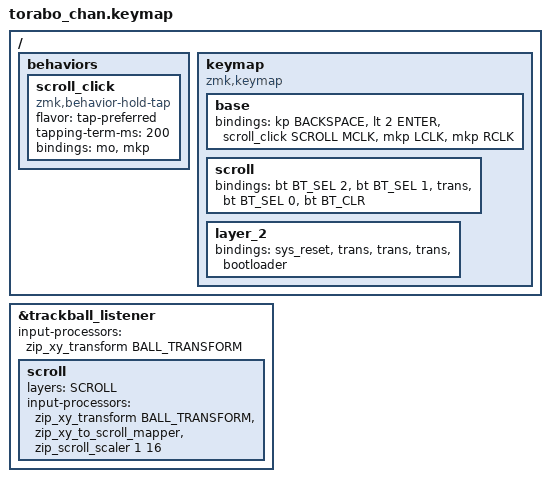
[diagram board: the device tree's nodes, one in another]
#include <dt-bindings/zmk/input_transform.h>
#include <input/processors.dtsi>
#include <behaviors.dtsi>
#include <dt-bindings/zmk/bt.h>
#include <dt-bindings/zmk/keys.h>
#include <dt-bindings/zmk/pointing.h>

#define BASE 0
#define SCROLL 1

// MCU on the right: rotate the previous cursor output (x, y) -> (y, -x).
// Composed with the previous swap + Y inversion, raw input becomes (-x, -y).

#define BALL_TRANSFORM (INPUT_TRANSFORM_X_INVERT | INPUT_TRANSFORM_Y_INVERT)

&trackball_listener {
    // Use the same mounting correction for pointer motion and ball scrolling.

    input-processors = <&zip_xy_transform BALL_TRANSFORM>;

    scroll {
        layers = <SCROLL>;
        input-processors =
            <&zip_xy_transform BALL_TRANSFORM>,
            <&zip_xy_to_scroll_mapper>,
            <&zip_scroll_scaler 1 16>;
    };
};

/ {
    behaviors {
        scroll_click: scroll_click {
            compatible = "zmk,behavior-hold-tap";
            #binding-cells = <2>;
            flavor = "tap-preferred";
            tapping-term-ms = <200>;
            bindings = <&mo>, <&mkp>;
        };
    };

    keymap {
        compatible = "zmk,keymap";

        // Physical layout (MCU on the right), bindings remain SW1..SW5:
        // SW4  SW5
        // SW3       MCU ->
        // SW2  SW1

        base {
            bindings = <
&kp BACKSPACE  &lt 2 ENTER  &scroll_click SCROLL MCLK  &mkp LCLK  &mkp RCLK
            >;
        };

        scroll {
            bindings = <
&bt BT_SEL 2  &bt BT_SEL 1  &trans  &bt BT_SEL 0  &bt BT_CLR
            >;
        };

        layer_2 {
            bindings = <
&sys_reset  &trans  &trans  &trans  &bootloader
            >;
        };
    };
};
